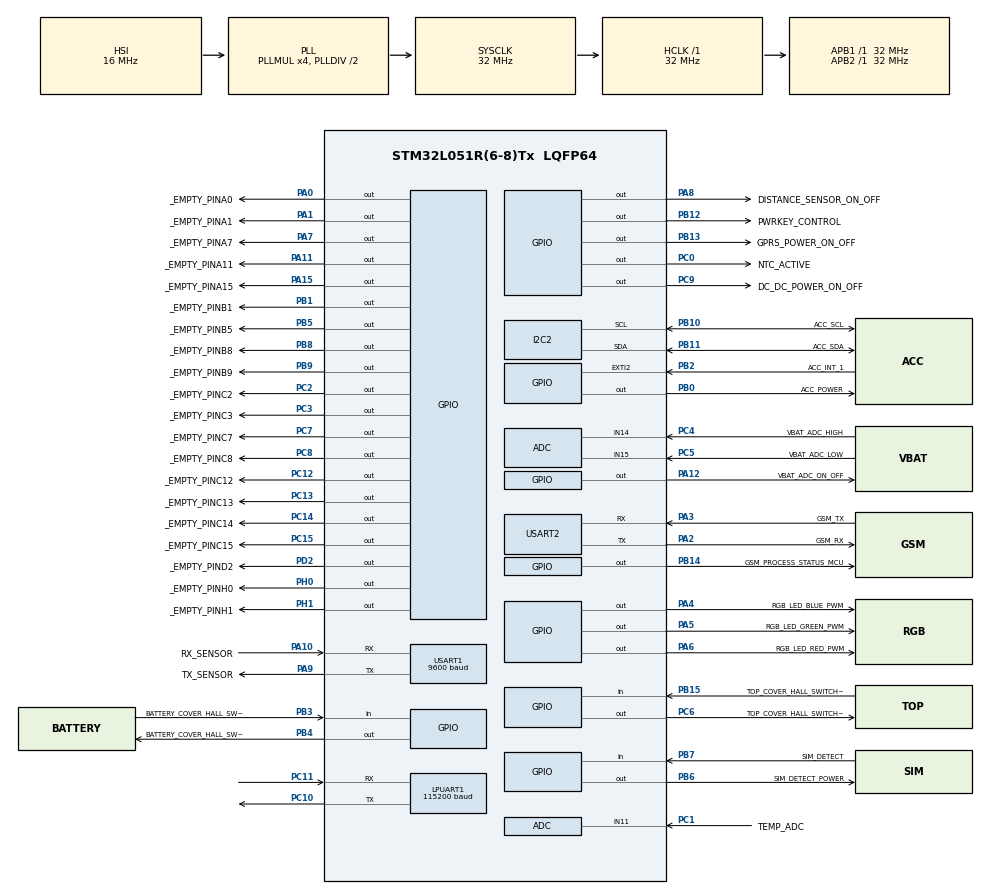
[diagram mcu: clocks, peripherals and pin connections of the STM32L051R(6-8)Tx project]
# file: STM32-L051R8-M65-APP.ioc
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ADC.ContinuousConvMode=ENABLE
ADC.DMAContinuousRequests=ENABLE
ADC.EOCSelection=ADC_EOC_SEQ_CONV
ADC.Overrun=ADC_OVR_DATA_PRESERVED
ADC.SamplingTime=ADC_SAMPLETIME_160CYCLES_5
Dma.ADC.0.Direction=DMA_PERIPH_TO_MEMORY
Dma.ADC.0.Instance=DMA1_Channel1
Dma.ADC.0.MemDataAlignment=DMA_MDATAALIGN_HALFWORD
Dma.ADC.0.MemInc=DMA_MINC_ENABLE
Dma.ADC.0.Mode=DMA_CIRCULAR
Dma.ADC.0.PeriphDataAlignment=DMA_PDATAALIGN_HALFWORD
Dma.ADC.0.PeriphInc=DMA_PINC_DISABLE
Dma.ADC.0.Priority=DMA_PRIORITY_LOW
Dma.Request0=ADC
I2C2.NoStretchMode=I2C_NOSTRETCH_DISABLE
I2C2.Timing=0x00707CBB
IWDG.Prescaler=IWDG_PRESCALER_256
IWDG.Reload=2048
IWDG.Window=4095
LPUART1.BaudRate=115200
LPUART1.WordLength=UART_WORDLENGTH_8B
Mcu.Family=STM32L0
Mcu.Name=STM32L051R(6-8)Tx
Mcu.Package=LQFP64
NVIC.ADC1_COMP_IRQn=true\:1\:0\:true\:false\:true\:true\:true\:true
NVIC.DMA1_Channel1_IRQn=true\:2\:0\:true\:false\:true\:false\:true\:true
NVIC.EXTI2_3_IRQn=true\:0\:0\:false\:false\:true\:true\:true\:true
NVIC.RTC_IRQn=true\:0\:0\:false\:false\:true\:true\:true\:true
NVIC.TIM6_DAC_IRQn=true\:0\:0\:false\:false\:true\:true\:true\:true
NVIC.USART1_IRQn=true\:0\:0\:false\:false\:true\:true\:true\:true
NVIC.USART2_IRQn=true\:0\:0\:false\:false\:true\:true\:true\:true
PA0.GPIO_Label=_EMPTY_PINA0
PA0.Signal=GPIO_Output
PA1.GPIO_Label=_EMPTY_PINA1
PA1.Signal=GPIO_Output
PA10.GPIO_Label=RX_SENSOR
PA10.Mode=Asynchronous
PA10.Signal=USART1_RX
PA11.GPIO_Label=_EMPTY_PINA11
PA11.Signal=GPIO_Output
PA12.GPIO_Label=VBAT_ADC_ON_OFF
PA12.Signal=GPIO_Output
PA13.Mode=Serial_Wire
PA13.Signal=SYS_SWDIO
PA14.Mode=Serial_Wire
PA14.Signal=SYS_SWCLK
PA15.GPIO_Label=_EMPTY_PINA15
PA15.Signal=GPIO_Output
PA2.GPIO_Label=GSM_RX
PA2.Mode=Asynchronous
PA2.Signal=USART2_TX
PA3.GPIO_Label=GSM_TX
PA3.Mode=Asynchronous
PA3.Signal=USART2_RX
PA4.GPIO_Label=RGB_LED_BLUE_PWM
PA4.GPIO_Speed=GPIO_SPEED_FREQ_VERY_HIGH
PA4.Signal=GPIO_Output
PA5.GPIO_Label=RGB_LED_GREEN_PWM
PA5.GPIO_Speed=GPIO_SPEED_FREQ_VERY_HIGH
PA5.Signal=GPIO_Output
PA6.GPIO_Label=RGB_LED_RED_PWM
PA6.GPIO_Speed=GPIO_SPEED_FREQ_VERY_HIGH
PA6.Signal=GPIO_Output
PA7.GPIO_Label=_EMPTY_PINA7
PA7.Signal=GPIO_Output
PA8.GPIO_Label=DISTANCE_SENSOR_ON_OFF
PA8.Signal=GPIO_Output
PA9.GPIO_Label=TX_SENSOR
PA9.Mode=Asynchronous
PA9.Signal=USART1_TX
PB0.GPIO_Label=ACC_POWER
PB0.Signal=GPIO_Output
PB1.GPIO_Label=_EMPTY_PINB1
PB1.Signal=GPIO_Output
PB10.GPIO_Label=ACC_SCL
PB10.GPIO_Pu=GPIO_PULLUP
PB10.GPIO_Speed=GPIO_SPEED_FREQ_VERY_HIGH
PB10.Mode=I2C
PB10.Signal=I2C2_SCL
PB11.GPIO_Label=ACC_SDA
PB11.GPIO_Pu=GPIO_PULLUP
PB11.GPIO_Speed=GPIO_SPEED_FREQ_VERY_HIGH
PB11.Mode=I2C
PB11.Signal=I2C2_SDA
PB12.GPIO_Label=PWRKEY_CONTROL
PB12.Signal=GPIO_Output
PB13.GPIO_Label=GPRS_POWER_ON_OFF
PB13.Signal=GPIO_Output
PB14.GPIO_Label=GSM_PROCESS_STATUS_MCU
PB14.Signal=GPIO_Output
PB15.GPIO_Label=TOP_COVER_HALL_SWITCH_OUT_INT
PB15.Signal=GPIO_Input
PB2.GPIO_Label=ACC_INT_1
PB2.Signal=GPXTI2
PB3.GPIO_Label=BATTERY_COVER_HALL_SWITCH_OUT_INT
PB3.Signal=GPIO_Input
PB4.GPIO_Label=BATTERY_COVER_HALL_SWITCH_POWER
PB4.Signal=GPIO_Output
PB5.GPIO_Label=_EMPTY_PINB5
PB5.Signal=GPIO_Output
PB6.GPIO_Label=SIM_DETECT_POWER
PB6.GPIO_PuPd=GPIO_NOPULL
PB6.GPIO_Speed=GPIO_SPEED_FREQ_HIGH
PB6.Signal=GPIO_Output
PB7.GPIO_Label=SIM_DETECT
PB7.Signal=GPIO_Input
PB8.GPIO_Label=_EMPTY_PINB8
PB8.Signal=GPIO_Output
PB9.GPIO_Label=_EMPTY_PINB9
PB9.Signal=GPIO_Output
PC0.GPIO_Label=NTC_ACTIVE
PC0.Signal=GPIO_Output
PC1.GPIO_Label=TEMP_ADC
PC1.Mode=IN11
PC1.Signal=ADC_IN11
PC10.Mode=Asynchronous
PC10.Signal=LPUART1_TX
PC11.Mode=Asynchronous
PC11.Signal=LPUART1_RX
PC12.GPIO_Label=_EMPTY_PINC12
PC12.Signal=GPIO_Output
PC13.GPIO_Label=_EMPTY_PINC13
PC13.Signal=GPIO_Output
PC14-OSC32_IN.GPIO_Label=_EMPTY_PINC14
PC14-OSC32_IN.Signal=GPIO_Output
PC15-OSC32_OUT.GPIO_Label=_EMPTY_PINC15
PC15-OSC32_OUT.Signal=GPIO_Output
PC2.GPIO_Label=_EMPTY_PINC2
PC2.Signal=GPIO_Output
PC3.GPIO_Label=_EMPTY_PINC3
PC3.Signal=GPIO_Output
PC4.GPIO_Label=VBAT_ADC_HIGH
PC4.Mode=IN14
PC4.Signal=ADC_IN14
PC5.GPIO_Label=VBAT_ADC_LOW
PC5.Mode=IN15
PC5.Signal=ADC_IN15
PC6.GPIO_Label=TOP_COVER_HALL_SWITCH_POWER
PC6.Signal=GPIO_Output
PC7.GPIO_Label=_EMPTY_PINC7
PC7.Signal=GPIO_Output
PC8.GPIO_Label=_EMPTY_PINC8
PC8.Signal=GPIO_Output
PC9.GPIO_Label=DC_DC_POWER_ON_OFF
PC9.Signal=GPIO_Output
PD2.GPIO_Label=_EMPTY_PIND2
PD2.Signal=GPIO_Output
PH0-OSC_IN.GPIO_Label=_EMPTY_PINH0
PH0-OSC_IN.Signal=GPIO_Output
PH1-OSC_OUT.GPIO_Label=_EMPTY_PINH1
PH1-OSC_OUT.Signal=GPIO_Output
ProjectManager.HeapSize=0x200
ProjectManager.StackSize=0x400
ProjectManager.TargetToolchain=EWARM V7
RCC.AHBFreq_Value=32000000
RCC.APB1Freq_Value=32000000
RCC.APB1TimFreq_Value=32000000
RCC.APB2Freq_Value=32000000
RCC.APB2TimFreq_Value=32000000
RCC.HCLKFreq_Value=32000000
RCC.HSE_VALUE=8000000
RCC.HSI16_VALUE=16000000
RCC.HSI_VALUE=16000000
RCC.LSE_VALUE=32768
RCC.MSI_VALUE=2097000
RCC.PLLMUL=RCC_PLLMUL_4
RCC.SYSCLKFreq_VALUE=32000000
RCC.SYSCLKSource=RCC_SYSCLKSOURCE_PLLCLK
RCC.VCOOutputFreq_Value=64000000
RTC.Month=RTC_MONTH_JANUARY
RTC.Seconds=0
RTC.SynchPrediv=288
RTC.WakeUpClock-WakeUp=RTC_WAKEUPCLOCK_CK_SPRE_16BITS
RTC.WakeUpCounter-WakeUp=10
RTC.Year=0
TIM2.ClockDivision=TIM_CLOCKDIVISION_DIV1
TIM2.Prescaler=31
TIM6.Period=999
TIM6.Prescaler=32
USART1.BaudRate=9600
USART1.VirtualMode-Asynchronous=VM_ASYNC
USART2.VirtualMode-Asynchronous=VM_ASYNC
VP_ADC_Vref_Input.Mode=IN-Vrefint
VP_IWDG_VS_IWDG.Mode=IWDG_Activate
VP_RTC_VS_RTC_Activate.Mode=RTC_Enabled
VP_RTC_VS_RTC_Calendar.Mode=RTC_Calendar
VP_RTC_VS_RTC_WakeUp_intern.Mode=WakeUp
VP_TIM2_VS_ClockSourceINT.Mode=Internal
VP_TIM6_VS_ClockSourceINT.Mode=Enable_Timer
board=custom

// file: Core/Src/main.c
/* USER CODE BEGIN Header */
/**
 ******************************************************************************
 * @file           : main.c
 * @brief          : Main program body
 ******************************************************************************
 * @attention
 *
 * Copyright (c) 2023 STMicroelectronics.
 * All rights reserved.
 *
 * This software is licensed under terms that can be found in the LICENSE file
 * in the root directory of this software component.
 * If no LICENSE file comes with this software, it is provided AS-IS.
 *
 ******************************************************************************
 */
/* USER CODE END Header */
#include "main.h"
#include "adc.h"
#include "dma.h"
#include "i2c.h"
#include "iwdg.h"
#include "usart.h"
#include "rtc.h"
#include "tim.h"
#include "gpio.h"

/* USER CODE BEGIN Includes */
#include "usr_general.h"
/* USER CODE END Includes */

void SystemClock_Config(void);

int main(void)
{

  /* MCU Configuration--------------------------------------------------------*/

  /* Reset of all peripherals, Initializes the Flash interface and the Systick. */
  HAL_Init();

  /* Configure the system clock */
  SystemClock_Config();

  /* Initialize all configured peripherals */
  MX_GPIO_Init();
  MX_DMA_Init();
  MX_USART1_UART_Init();
  MX_USART2_UART_Init();
  MX_LPUART1_UART_Init();
  MX_ADC_Init();
  MX_I2C2_Init();
  MX_IWDG_Init();
  MX_RTC_Init();
  MX_TIM2_Init();
  MX_TIM6_Init();
  /* USER CODE BEGIN 2 */

  UsrSystemInitial();
  /* USER CODE END 2 */

  /* Infinite loop */
  while (1)
  {

    /* USER CODE BEGIN 3 */

    UsrSystemGeneral();
  }
  /* USER CODE END 3 */
}

void SystemClock_Config(void)
{
  RCC_OscInitTypeDef RCC_OscInitStruct = {0};
  RCC_ClkInitTypeDef RCC_ClkInitStruct = {0};
  RCC_PeriphCLKInitTypeDef PeriphClkInit = {0};

  /** Configure the main internal regulator output voltage
  */
  __HAL_PWR_VOLTAGESCALING_CONFIG(PWR_REGULATOR_VOLTAGE_SCALE1);

  /** Initializes the RCC Oscillators according to the specified parameters
  * in the RCC_OscInitTypeDef structure.
  */
  RCC_OscInitStruct.OscillatorType = RCC_OSCILLATORTYPE_HSI|RCC_OSCILLATORTYPE_LSI;
  RCC_OscInitStruct.HSIState = RCC_HSI_ON;
  RCC_OscInitStruct.HSICalibrationValue = RCC_HSICALIBRATION_DEFAULT;
  RCC_OscInitStruct.LSIState = RCC_LSI_ON;
  RCC_OscInitStruct.PLL.PLLState = RCC_PLL_ON;
  RCC_OscInitStruct.PLL.PLLSource = RCC_PLLSOURCE_HSI;
  RCC_OscInitStruct.PLL.PLLMUL = RCC_PLLMUL_4;
  RCC_OscInitStruct.PLL.PLLDIV = RCC_PLLDIV_2;
  if (HAL_RCC_OscConfig(&RCC_OscInitStruct) != HAL_OK)
  {
    Error_Handler();
  }

  /** Initializes the CPU, AHB and APB buses clocks
  */
  RCC_ClkInitStruct.ClockType = RCC_CLOCKTYPE_HCLK|RCC_CLOCKTYPE_SYSCLK
                              |RCC_CLOCKTYPE_PCLK1|RCC_CLOCKTYPE_PCLK2;
  RCC_ClkInitStruct.SYSCLKSource = RCC_SYSCLKSOURCE_PLLCLK;
  RCC_ClkInitStruct.AHBCLKDivider = RCC_SYSCLK_DIV1;
  RCC_ClkInitStruct.APB1CLKDivider = RCC_HCLK_DIV1;
  RCC_ClkInitStruct.APB2CLKDivider = RCC_HCLK_DIV1;

  if (HAL_RCC_ClockConfig(&RCC_ClkInitStruct, FLASH_LATENCY_1) != HAL_OK)
  {
    Error_Handler();
  }
  PeriphClkInit.PeriphClockSelection = RCC_PERIPHCLK_USART1|RCC_PERIPHCLK_USART2
                              |RCC_PERIPHCLK_LPUART1|RCC_PERIPHCLK_RTC;
  PeriphClkInit.Usart1ClockSelection = RCC_USART1CLKSOURCE_PCLK2;
  PeriphClkInit.Usart2ClockSelection = RCC_USART2CLKSOURCE_PCLK1;
  PeriphClkInit.Lpuart1ClockSelection = RCC_LPUART1CLKSOURCE_PCLK1;
  PeriphClkInit.RTCClockSelection = RCC_RTCCLKSOURCE_LSI;
  if (HAL_RCCEx_PeriphCLKConfig(&PeriphClkInit) != HAL_OK)
  {
    Error_Handler();
  }
}

void Error_Handler(void)
{
  __disable_irq();
  while (1)
  {
  }
}
